AUTOSAR XML (schema 4-2-2)
package /STELLANTIS/EPT/ASWCs
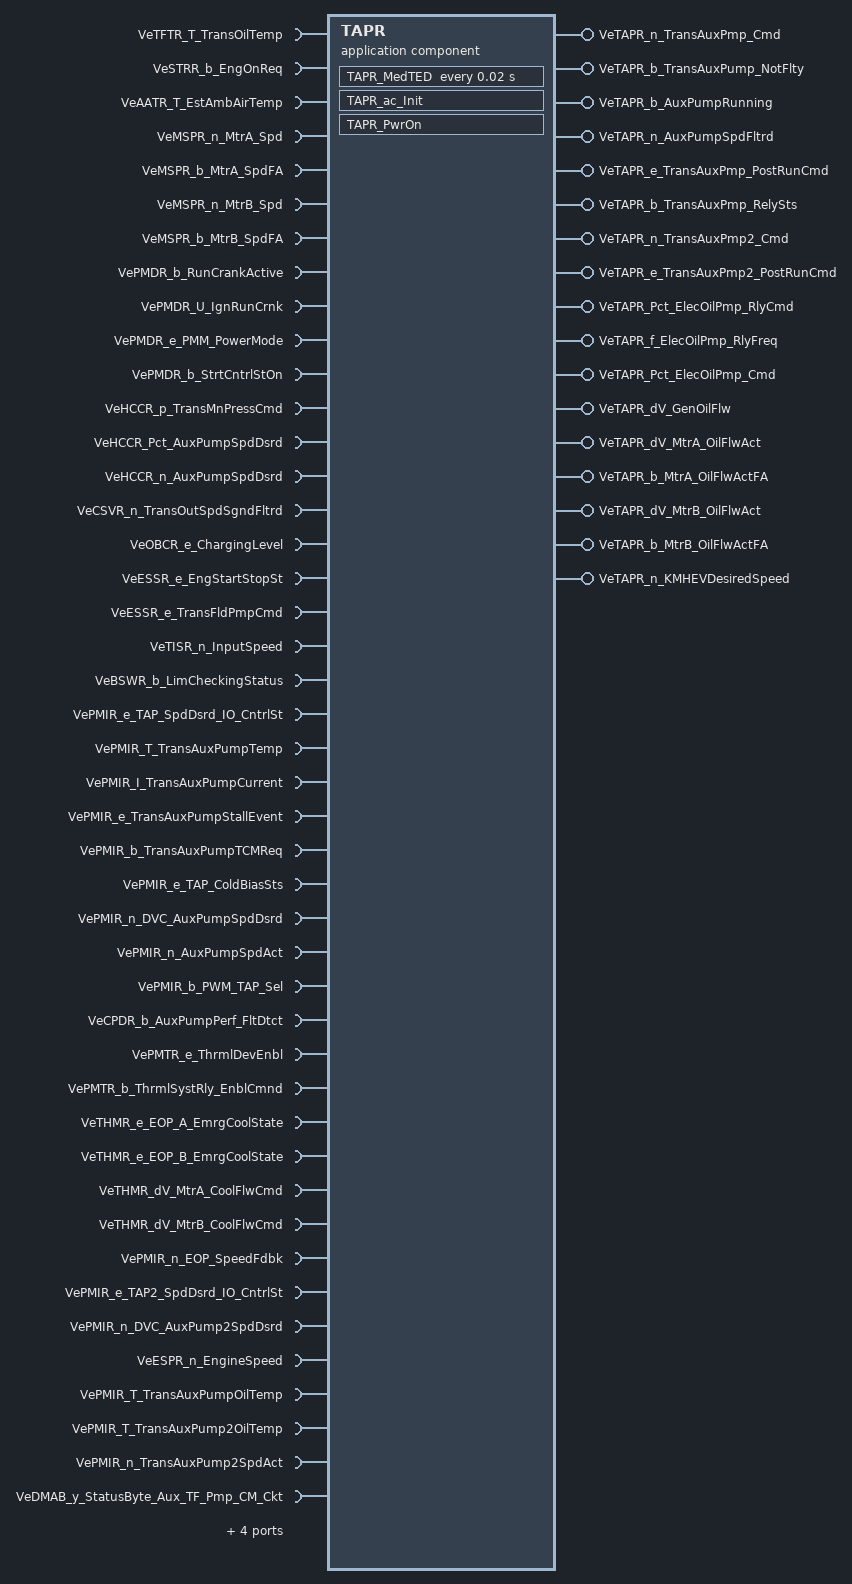
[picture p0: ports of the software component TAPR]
  application sw component type TAPR
    48 x require port:
      VeTFTR_T_TransOilTemp: variation-point={short-label=vpVeTFTR_T_TransOilTemp, sw-syscond=1}, nonqueued-receiver-com-spec{data-element=Value, init-value=0}, required-interface=VeTFTR_T_TransOilTemp
      VeSTRR_b_EngOnReq: variation-point={short-label=vpVeSTRR_b_EngOnReq, sw-syscond=1}, nonqueued-receiver-com-spec{data-element=Value, init-value=0}, required-interface=VeSTRR_b_EngOnReq
      VeAATR_T_EstAmbAirTemp: variation-point={short-label=vpVeAATR_T_EstAmbAirTemp, sw-syscond=1}, nonqueued-receiver-com-spec{data-element=Value, init-value=0}, required-interface=VeAATR_T_EstAmbAirTemp
      VeMSPR_n_MtrA_Spd: variation-point={short-label=vpVeMSPR_n_MtrA_Spd, sw-syscond=1}, nonqueued-receiver-com-spec{data-element=Value, init-value=0}, required-interface=VeMSPR_n_MtrA_Spd
      VeMSPR_b_MtrA_SpdFA: variation-point={short-label=vpVeMSPR_b_MtrA_SpdFA, sw-syscond=1}, nonqueued-receiver-com-spec{data-element=Value, init-value=0}, required-interface=VeMSPR_b_MtrA_SpdFA
      VeMSPR_n_MtrB_Spd: variation-point={short-label=vpVeMSPR_n_MtrB_Spd, sw-syscond=1}, nonqueued-receiver-com-spec{data-element=Value, init-value=0}, required-interface=VeMSPR_n_MtrB_Spd
      VeMSPR_b_MtrB_SpdFA: variation-point={short-label=vpVeMSPR_b_MtrB_SpdFA, sw-syscond=1}, nonqueued-receiver-com-spec{data-element=Value, init-value=0}, required-interface=VeMSPR_b_MtrB_SpdFA
      VePMDR_b_RunCrankActive: variation-point={short-label=vpVePMDR_b_RunCrankActive, sw-syscond=1}, nonqueued-receiver-com-spec{data-element=Value, init-value=0}, required-interface=VePMDR_b_RunCrankActive
      VePMDR_U_IgnRunCrnk: variation-point={short-label=vpVePMDR_U_IgnRunCrnk, sw-syscond=1}, nonqueued-receiver-com-spec{data-element=Value, init-value=0}, required-interface=VePMDR_U_IgnRunCrnk
      VePMDR_e_PMM_PowerMode: variation-point={short-label=vpVePMDR_e_PMM_PowerMode, sw-syscond=1}, nonqueued-receiver-com-spec{data-element=Value, init-value=CePMDR_e_PowerMode_Off}, required-interface=VePMDR_e_PMM_PowerMode
      VePMDR_b_StrtCntrlStOn: variation-point={short-label=vpVePMDR_b_StrtCntrlStOn, sw-syscond=1}, nonqueued-receiver-com-spec{data-element=Value, init-value=0}, required-interface=VePMDR_b_StrtCntrlStOn
      VeHCCR_p_TransMnPressCmd: variation-point={short-label=vpVeHCCR_p_TransMnPressCmd, sw-syscond=1}, nonqueued-receiver-com-spec{data-element=Value, init-value=0}, required-interface=VeHCCR_p_TransMnPressCmd
      VeHCCR_Pct_AuxPumpSpdDsrd: variation-point={short-label=vpVeHCCR_Pct_AuxPumpSpdDsrd, sw-syscond=1}, nonqueued-receiver-com-spec{data-element=Value, init-value=0}, required-interface=VeHCCR_Pct_AuxPumpSpdDsrd
      VeHCCR_n_AuxPumpSpdDsrd: variation-point={short-label=vpVeHCCR_n_AuxPumpSpdDsrd, sw-syscond=1}, nonqueued-receiver-com-spec{data-element=Value, init-value=0}, required-interface=VeHCCR_n_AuxPumpSpdDsrd
      VeCSVR_n_TransOutSpdSgndFltrd: variation-point={short-label=vpVeCSVR_n_TransOutSpdSgndFltrd, sw-syscond=1}, nonqueued-receiver-com-spec{data-element=Value, init-value=0}, required-interface=VeCSVR_n_TransOutSpdSgndFltrd
      VeOBCR_e_ChargingLevel: variation-point={short-label=vpVeOBCR_e_ChargingLevel, sw-syscond=1}, nonqueued-receiver-com-spec{data-element=Value, init-value=CeOBCR_e_ChargingLvlDefault}, required-interface=VeOBCR_e_ChargingLevel
      VeESSR_e_EngStartStopSt: variation-point={short-label=vpVeESSR_e_EngStartStopSt, sw-syscond=1}, nonqueued-receiver-com-spec{data-element=Value, init-value=CeESSR_e_EngOff}, required-interface=VeESSR_e_EngStartStopSt
      VeESSR_e_TransFldPmpCmd: variation-point={short-label=vpVeESSR_e_TransFldPmpCmd, sw-syscond=1}, nonqueued-receiver-com-spec{data-element=Value, init-value=CeESSR_e_Normal}, required-interface=VeESSR_e_TransFldPmpCmd
      VeTISR_n_InputSpeed: variation-point={short-label=vpVeTISR_n_InputSpeed, sw-syscond=1}, nonqueued-receiver-com-spec{data-element=Value, init-value=0}, required-interface=VeTISR_n_InputSpeed
      VeBSWR_b_LimCheckingStatus: variation-point={short-label=vpVeBSWR_b_LimCheckingStatus, sw-syscond=1}, nonqueued-receiver-com-spec{data-element=Value, init-value=0}, required-interface=VeBSWR_b_LimCheckingStatus
      VePMIR_e_TAP_SpdDsrd_IO_CntrlSt: variation-point={short-label=vpVePMIR_e_TAP_SpdDsrd_IO_CntrlSt, sw-syscond=1}, nonqueued-receiver-com-spec{data-element=Value, init-value=CeTAIR_e_Return_Control_to_ECU}, required-interface=VePMIR_e_TAP_SpdDsrd_IO_CntrlSt
      VePMIR_T_TransAuxPumpTemp: variation-point={short-label=vpVePMIR_T_TransAuxPumpTemp, sw-syscond=1}, nonqueued-receiver-com-spec{data-element=Value, init-value=0}, required-interface=VePMIR_T_TransAuxPumpTemp
      VePMIR_I_TransAuxPumpCurrent: variation-point={short-label=vpVePMIR_I_TransAuxPumpCurrent, sw-syscond=1}, nonqueued-receiver-com-spec{data-element=Value, init-value=0}, required-interface=VePMIR_I_TransAuxPumpCurrent
      VePMIR_e_TransAuxPumpStallEvent: variation-point={short-label=vpVePMIR_e_TransAuxPumpStallEvent, sw-syscond=1}, nonqueued-receiver-com-spec{data-element=Value, init-value=CeTAPR_e_StallEvnt_FALSE}, required-interface=VePMIR_e_TransAuxPumpStallEvent
      VePMIR_b_TransAuxPumpTCMReq: variation-point={short-label=vpVePMIR_b_TransAuxPumpTCMReq, sw-syscond=1}, nonqueued-receiver-com-spec{data-element=Value, init-value=0}, required-interface=VePMIR_b_TransAuxPumpTCMReq
      VePMIR_e_TAP_ColdBiasSts: variation-point={short-label=vpVePMIR_e_TAP_ColdBiasSts, sw-syscond=1}, nonqueued-receiver-com-spec{data-element=Value, init-value=CeTAPR_e_TAP_FalseTrueSNA_False}, required-interface=VePMIR_e_TAP_ColdBiasSts
      VePMIR_n_DVC_AuxPumpSpdDsrd: variation-point={short-label=vpVePMIR_n_DVC_AuxPumpSpdDsrd, sw-syscond=1}, nonqueued-receiver-com-spec{data-element=Value, init-value=0}, required-interface=VePMIR_n_DVC_AuxPumpSpdDsrd
      VePMIR_n_AuxPumpSpdAct: variation-point={short-label=vpVePMIR_n_AuxPumpSpdAct, sw-syscond=1}, nonqueued-receiver-com-spec{data-element=Value, init-value=0}, required-interface=VePMIR_n_AuxPumpSpdAct
      VePMIR_b_PWM_TAP_Sel: variation-point={short-label=vpVePMIR_b_PWM_TAP_Sel, sw-syscond=1}, nonqueued-receiver-com-spec{data-element=Value, init-value=0}, required-interface=VePMIR_b_PWM_TAP_Sel
      VeCPDR_b_AuxPumpPerf_FltDtct: variation-point={short-label=vpVeCPDR_b_AuxPumpPerf_FltDtct, sw-syscond=1}, nonqueued-receiver-com-spec{data-element=Value, init-value=0}, required-interface=VeCPDR_b_AuxPumpPerf_FltDtct
      VePMTR_e_ThrmlDevEnbl: variation-point={short-label=vpVePMTR_e_ThrmlDevEnbl, sw-syscond=1}, nonqueued-receiver-com-spec{data-element=Value, init-value=CePMTR_e_DISBL_All_Thrml}, required-interface=VePMTR_e_ThrmlDevEnbl
      VePMTR_b_ThrmlSystRly_EnblCmnd: variation-point={short-label=vpVePMTR_b_ThrmlSystRly_EnblCmnd, sw-syscond=1}, nonqueued-receiver-com-spec{data-element=Value, init-value=0}, required-interface=VePMTR_b_ThrmlSystRly_EnblCmnd
      VeTHMR_e_EOP_A_EmrgCoolState: variation-point={short-label=vpVeTHMR_e_EOP_A_EmrgCoolState, sw-syscond=1}, nonqueued-receiver-com-spec{data-element=Value, init-value=CeTHMR_e_OilPumpEmrgCool_OFF}, required-interface=VeTHMR_e_EOP_A_EmrgCoolState
      VeTHMR_e_EOP_B_EmrgCoolState: variation-point={short-label=vpVeTHMR_e_EOP_B_EmrgCoolState, sw-syscond=1}, nonqueued-receiver-com-spec{data-element=Value, init-value=CeTHMR_e_OilPumpEmrgCool_OFF}, required-interface=VeTHMR_e_EOP_B_EmrgCoolState
      VeTHMR_dV_MtrA_CoolFlwCmd: variation-point={short-label=vpVeTHMR_dV_MtrA_CoolFlwCmd, sw-syscond=1}, nonqueued-receiver-com-spec{data-element=Value, init-value=0}, required-interface=VeTHMR_dV_MtrA_CoolFlwCmd
      VeTHMR_dV_MtrB_CoolFlwCmd: variation-point={short-label=vpVeTHMR_dV_MtrB_CoolFlwCmd, sw-syscond=1}, nonqueued-receiver-com-spec{data-element=Value, init-value=0}, required-interface=VeTHMR_dV_MtrB_CoolFlwCmd
      VePMIR_n_EOP_SpeedFdbk: variation-point={short-label=vpVePMIR_n_EOP_SpeedFdbk, sw-syscond=1}, nonqueued-receiver-com-spec{data-element=Value, init-value=0}, required-interface=VePMIR_n_EOP_SpeedFdbk
      VePMIR_e_TAP2_SpdDsrd_IO_CntrlSt: variation-point={short-label=vpVePMIR_e_TAP2_SpdDsrd_IO_CntrlSt, sw-syscond=1}, nonqueued-receiver-com-spec{data-element=Value, init-value=CeTAIR_e_Return_Control_to_ECU}, required-interface=VePMIR_e_TAP2_SpdDsrd_IO_CntrlSt
      VePMIR_n_DVC_AuxPump2SpdDsrd: variation-point={short-label=vpVePMIR_n_DVC_AuxPump2SpdDsrd, sw-syscond=1}, nonqueued-receiver-com-spec{data-element=Value, init-value=0}, required-interface=VePMIR_n_DVC_AuxPump2SpdDsrd
      VeESPR_n_EngineSpeed: variation-point={short-label=vpVeESPR_n_EngineSpeed, sw-syscond=1}, nonqueued-receiver-com-spec{data-element=Value, init-value=0}, required-interface=VeESPR_n_EngineSpeed
      VePMIR_T_TransAuxPumpOilTemp: variation-point={short-label=vpVePMIR_T_TransAuxPumpOilTemp, sw-syscond=1}, nonqueued-receiver-com-spec{data-element=Value, init-value=0}, required-interface=VePMIR_T_TransAuxPumpOilTemp
      VePMIR_T_TransAuxPump2OilTemp: variation-point={short-label=vpVePMIR_T_TransAuxPump2OilTemp, sw-syscond=1}, nonqueued-receiver-com-spec{data-element=Value, init-value=0}, required-interface=VePMIR_T_TransAuxPump2OilTemp
      VePMIR_n_TransAuxPump2SpdAct: variation-point={short-label=vpVePMIR_n_TransAuxPump2SpdAct, sw-syscond=1}, nonqueued-receiver-com-spec{data-element=Value, init-value=0}, required-interface=VePMIR_n_TransAuxPump2SpdAct
      VeDMAB_y_StatusByte_Aux_TF_Pmp_CM_Ckt: nonqueued-receiver-com-spec{data-element=Value, init-value=0}, required-interface=VeDMAB_y_StatusByte_Aux_TF_Pmp_CM_Ckt
      VeDMAB_y_StatusByte_Aux_TF_Pmp_CM_Fdbck: nonqueued-receiver-com-spec{data-element=Value, init-value=0}, required-interface=VeDMAB_y_StatusByte_Aux_TF_Pmp_CM_Fdbck
      VeDMAB_y_StatusByte_Aux_TF_Pmp_CM_Fdbck_SigRan: nonqueued-receiver-com-spec{data-element=Value, init-value=0}, required-interface=VeDMAB_y_StatusByte_Aux_TF_Pmp_CM_Fdbck_SigRan
      VePMIR_e_PWM_EOP_IOCtrlMode: variation-point={short-label=vpVePMIR_e_PWM_EOP_IOCtrlMode, sw-syscond=1}, nonqueued-receiver-com-spec{data-element=Value, init-value=CeTAIR_e_Return_Control_to_ECU}, required-interface=VePMIR_e_PWM_EOP_IOCtrlMode
      VePMIR_Pct_PWM_EOP_IOCtrlSpd: variation-point={short-label=vpVePMIR_Pct_PWM_EOP_IOCtrlSpd, sw-syscond=1}, nonqueued-receiver-com-spec{data-element=Value, init-value=0}, required-interface=VePMIR_Pct_PWM_EOP_IOCtrlSpd
    17 x provide port:
      VeTAPR_n_TransAuxPmp_Cmd: variation-point={short-label=vpVeTAPR_n_TransAuxPmp_Cmd, sw-syscond=1}, nonqueued-sender-com-spec{data-element=Value, init-value=0}, provided-interface=VeTAPR_n_TransAuxPmp_Cmd
      VeTAPR_b_TransAuxPump_NotFlty: variation-point={short-label=vpVeTAPR_b_TransAuxPump_NotFlty, sw-syscond=1}, nonqueued-sender-com-spec{data-element=Value, init-value=0}, provided-interface=VeTAPR_b_TransAuxPump_NotFlty
      VeTAPR_b_AuxPumpRunning: variation-point={short-label=vpVeTAPR_b_AuxPumpRunning, sw-syscond=1}, nonqueued-sender-com-spec{data-element=Value, init-value=0}, provided-interface=VeTAPR_b_AuxPumpRunning
      VeTAPR_n_AuxPumpSpdFltrd: variation-point={short-label=vpVeTAPR_n_AuxPumpSpdFltrd, sw-syscond=1}, nonqueued-sender-com-spec{data-element=Value, init-value=0}, provided-interface=VeTAPR_n_AuxPumpSpdFltrd
      VeTAPR_e_TransAuxPmp_PostRunCmd: variation-point={short-label=vpVeTAPR_e_TransAuxPmp_PostRunCmd, sw-syscond=1}, nonqueued-sender-com-spec{data-element=Value, init-value=CeTAPR_e_TAP_PostRunCmd_NoPostRun}, provided-interface=VeTAPR_e_TransAuxPmp_PostRunCmd
      VeTAPR_b_TransAuxPmp_RelySts: variation-point={short-label=vpVeTAPR_b_TransAuxPmp_RelySts, sw-syscond=1}, nonqueued-sender-com-spec{data-element=Value, init-value=0}, provided-interface=VeTAPR_b_TransAuxPmp_RelySts
      VeTAPR_n_TransAuxPmp2_Cmd: variation-point={short-label=vpVeTAPR_n_TransAuxPmp2_Cmd, sw-syscond=1}, nonqueued-sender-com-spec{data-element=Value, init-value=0}, provided-interface=VeTAPR_n_TransAuxPmp2_Cmd
      VeTAPR_e_TransAuxPmp2_PostRunCmd: variation-point={short-label=vpVeTAPR_e_TransAuxPmp2_PostRunCmd, sw-syscond=1}, nonqueued-sender-com-spec{data-element=Value, init-value=CeTAPR_e_TAP_PostRunCmd_NoPostRun}, provided-interface=VeTAPR_e_TransAuxPmp2_PostRunCmd
      VeTAPR_Pct_ElecOilPmp_RlyCmd: variation-point={short-label=vpVeTAPR_Pct_ElecOilPmp_RlyCmd, sw-syscond=1}, nonqueued-sender-com-spec{data-element=Value, init-value=0}, provided-interface=VeTAPR_Pct_ElecOilPmp_RlyCmd
      VeTAPR_f_ElecOilPmp_RlyFreq: variation-point={short-label=vpVeTAPR_f_ElecOilPmp_RlyFreq, sw-syscond=1}, nonqueued-sender-com-spec{data-element=Value, init-value=0}, provided-interface=VeTAPR_f_ElecOilPmp_RlyFreq
      VeTAPR_Pct_ElecOilPmp_Cmd: variation-point={short-label=vpVeTAPR_Pct_ElecOilPmp_Cmd, sw-syscond=1}, nonqueued-sender-com-spec{data-element=Value, init-value=0}, provided-interface=VeTAPR_Pct_ElecOilPmp_Cmd
      VeTAPR_dV_GenOilFlw: variation-point={short-label=vpVeTAPR_dV_GenOilFlw, sw-syscond=1}, nonqueued-sender-com-spec{data-element=Value, init-value=0}, provided-interface=VeTAPR_dV_GenOilFlw
      VeTAPR_dV_MtrA_OilFlwAct: variation-point={short-label=vpVeTAPR_dV_MtrA_OilFlwAct, sw-syscond=1}, nonqueued-sender-com-spec{data-element=Value, init-value=0}, provided-interface=VeTAPR_dV_MtrA_OilFlwAct
      VeTAPR_b_MtrA_OilFlwActFA: variation-point={short-label=vpVeTAPR_b_MtrA_OilFlwActFA, sw-syscond=1}, nonqueued-sender-com-spec{data-element=Value, init-value=0}, provided-interface=VeTAPR_b_MtrA_OilFlwActFA
      VeTAPR_dV_MtrB_OilFlwAct: variation-point={short-label=vpVeTAPR_dV_MtrB_OilFlwAct, sw-syscond=1}, nonqueued-sender-com-spec{data-element=Value, init-value=0}, provided-interface=VeTAPR_dV_MtrB_OilFlwAct
      VeTAPR_b_MtrB_OilFlwActFA: variation-point={short-label=vpVeTAPR_b_MtrB_OilFlwActFA, sw-syscond=1}, nonqueued-sender-com-spec{data-element=Value, init-value=0}, provided-interface=VeTAPR_b_MtrB_OilFlwActFA
      VeTAPR_n_KMHEVDesiredSpeed: variation-point={short-label=vpVeTAPR_n_KMHEVDesiredSpeed, sw-syscond=1}, nonqueued-sender-com-spec{data-element=Value, init-value=0}, provided-interface=VeTAPR_n_KMHEVDesiredSpeed
    behavior IB_TAPR: data-type-mapping=msADTtoIDTMapping, handle-termination-and-restart=NO-SUPPORT
      timing event Event_MedTED: start-on-event=TAPR_MedTED, period=0.02
      init event Event_TAPR_ac_Init: start-on-event=TAPR_ac_Init
      init event Event_PwrOn: start-on-event=TAPR_PwrOn
      runnable TAPR_ac_Init
        data-send-points:
          access OUT_VeTAPR_e_TransAuxPmp_PostRunCmd_Value: accessed-variable=VeTAPR_e_TransAuxPmp_PostRunCmd.Value, variation-point={short-label=vpOUT_VeTAPR_e_TransAuxPmp_PostRunCmd_Value, sw-syscond=1}
          access OUT_VeTAPR_e_TransAuxPmp2_PostRunCmd_Value: accessed-variable=VeTAPR_e_TransAuxPmp2_PostRunCmd.Value, variation-point={short-label=vpOUT_VeTAPR_e_TransAuxPmp2_PostRunCmd_Value, sw-syscond=1}
      runnable TAPR_PwrOn
        data-send-points:
          17 x access:
            OUT_VeTAPR_b_TransAuxPmp_RelySts_Value: accessed-variable=VeTAPR_b_TransAuxPmp_RelySts.Value, variation-point={short-label=vpOUT_VeTAPR_b_TransAuxPmp_RelySts_Value, sw-syscond=1}
            OUT_VeTAPR_e_TransAuxPmp2_PostRunCmd_Value: accessed-variable=VeTAPR_e_TransAuxPmp2_PostRunCmd.Value, variation-point={short-label=vpOUT_VeTAPR_e_TransAuxPmp2_PostRunCmd_Value, sw-syscond=1}
            OUT_VeTAPR_n_TransAuxPmp_Cmd_Value: accessed-variable=VeTAPR_n_TransAuxPmp_Cmd.Value, variation-point={short-label=vpOUT_VeTAPR_n_TransAuxPmp_Cmd_Value, sw-syscond=1}
            OUT_VeTAPR_b_TransAuxPump_NotFlty_Value: accessed-variable=VeTAPR_b_TransAuxPump_NotFlty.Value, variation-point={short-label=vpOUT_VeTAPR_b_TransAuxPump_NotFlty_Value, sw-syscond=1}
            OUT_VeTAPR_n_AuxPumpSpdFltrd_Value: accessed-variable=VeTAPR_n_AuxPumpSpdFltrd.Value, variation-point={short-label=vpOUT_VeTAPR_n_AuxPumpSpdFltrd_Value, sw-syscond=1}
            OUT_VeTAPR_e_TransAuxPmp_PostRunCmd_Value: accessed-variable=VeTAPR_e_TransAuxPmp_PostRunCmd.Value, variation-point={short-label=vpOUT_VeTAPR_e_TransAuxPmp_PostRunCmd_Value, sw-syscond=1}
            OUT_VeTAPR_b_AuxPumpRunning_Value: accessed-variable=VeTAPR_b_AuxPumpRunning.Value, variation-point={short-label=vpOUT_VeTAPR_b_AuxPumpRunning_Value, sw-syscond=1}
            OUT_VeTAPR_Pct_ElecOilPmp_RlyCmd_Value: accessed-variable=VeTAPR_Pct_ElecOilPmp_RlyCmd.Value, variation-point={short-label=vpOUT_VeTAPR_Pct_ElecOilPmp_RlyCmd_Value, sw-syscond=1}
            OUT_VeTAPR_Pct_ElecOilPmp_Cmd_Value: accessed-variable=VeTAPR_Pct_ElecOilPmp_Cmd.Value, variation-point={short-label=vpOUT_VeTAPR_Pct_ElecOilPmp_Cmd_Value, sw-syscond=1}
            OUT_VeTAPR_f_ElecOilPmp_RlyFreq_Value: accessed-variable=VeTAPR_f_ElecOilPmp_RlyFreq.Value, variation-point={short-label=vpOUT_VeTAPR_f_ElecOilPmp_RlyFreq_Value, sw-syscond=1}
            OUT_VeTAPR_n_TransAuxPmp2_Cmd_Value: accessed-variable=VeTAPR_n_TransAuxPmp2_Cmd.Value, variation-point={short-label=vpOUT_VeTAPR_n_TransAuxPmp2_Cmd_Value, sw-syscond=1}
            OUT_VeTAPR_dV_GenOilFlw_Value: accessed-variable=VeTAPR_dV_GenOilFlw.Value, variation-point={short-label=vpOUT_VeTAPR_dV_GenOilFlw_Value, sw-syscond=1}
            OUT_VeTAPR_dV_MtrA_OilFlwAct_Value: accessed-variable=VeTAPR_dV_MtrA_OilFlwAct.Value, variation-point={short-label=vpOUT_VeTAPR_dV_MtrA_OilFlwAct_Value, sw-syscond=1}
            OUT_VeTAPR_b_MtrA_OilFlwActFA_Value: accessed-variable=VeTAPR_b_MtrA_OilFlwActFA.Value, variation-point={short-label=vpOUT_VeTAPR_b_MtrA_OilFlwActFA_Value, sw-syscond=1}
            OUT_VeTAPR_dV_MtrB_OilFlwAct_Value: accessed-variable=VeTAPR_dV_MtrB_OilFlwAct.Value, variation-point={short-label=vpOUT_VeTAPR_dV_MtrB_OilFlwAct_Value, sw-syscond=1}
            OUT_VeTAPR_b_MtrB_OilFlwActFA_Value: accessed-variable=VeTAPR_b_MtrB_OilFlwActFA.Value, variation-point={short-label=vpOUT_VeTAPR_b_MtrB_OilFlwActFA_Value, sw-syscond=1}
            OUT_VeTAPR_n_KMHEVDesiredSpeed_Value: accessed-variable=VeTAPR_n_KMHEVDesiredSpeed.Value, variation-point={short-label=vpOUT_VeTAPR_n_KMHEVDesiredSpeed_Value, sw-syscond=1}
      runnable TAPR_MedTED
        data-receive-point-by-arguments:
          48 x access:
            IN_VeAATR_T_EstAmbAirTemp_Value: accessed-variable=VeAATR_T_EstAmbAirTemp.Value, variation-point={short-label=vpIN_VeAATR_T_EstAmbAirTemp_Value, sw-syscond=1}
            IN_VeBSWR_b_LimCheckingStatus_Value: accessed-variable=VeBSWR_b_LimCheckingStatus.Value, variation-point={short-label=vpIN_VeBSWR_b_LimCheckingStatus_Value, sw-syscond=1}
            IN_VeCPDR_b_AuxPumpPerf_FltDtct_Value: accessed-variable=VeCPDR_b_AuxPumpPerf_FltDtct.Value, variation-point={short-label=vpIN_VeCPDR_b_AuxPumpPerf_FltDtct_Value, sw-syscond=1}
            IN_VeCSVR_n_TransOutSpdSgndFltrd_Value: accessed-variable=VeCSVR_n_TransOutSpdSgndFltrd.Value, variation-point={short-label=vpIN_VeCSVR_n_TransOutSpdSgndFltrd_Value, sw-syscond=1}
            IN_VeDMAB_y_StatusByte_Aux_TF_Pmp_CM_Ckt_Value: accessed-variable=VeDMAB_y_StatusByte_Aux_TF_Pmp_CM_Ckt.Value
            IN_VeDMAB_y_StatusByte_Aux_TF_Pmp_CM_Fdbck_Value: accessed-variable=VeDMAB_y_StatusByte_Aux_TF_Pmp_CM_Fdbck.Value
            IN_VeDMAB_y_StatusByte_Aux_TF_Pmp_CM_Fdbck_SigRan_Value: accessed-variable=VeDMAB_y_StatusByte_Aux_TF_Pmp_CM_Fdbck_SigRan.Value
            IN_VeESPR_n_EngineSpeed_Value: accessed-variable=VeESPR_n_EngineSpeed.Value, variation-point={short-label=vpIN_VeESPR_n_EngineSpeed_Value, sw-syscond=1}
            IN_VeESSR_e_EngStartStopSt_Value: accessed-variable=VeESSR_e_EngStartStopSt.Value, variation-point={short-label=vpIN_VeESSR_e_EngStartStopSt_Value, sw-syscond=1}
            IN_VeESSR_e_TransFldPmpCmd_Value: accessed-variable=VeESSR_e_TransFldPmpCmd.Value, variation-point={short-label=vpIN_VeESSR_e_TransFldPmpCmd_Value, sw-syscond=1}
            IN_VeHCCR_Pct_AuxPumpSpdDsrd_Value: accessed-variable=VeHCCR_Pct_AuxPumpSpdDsrd.Value, variation-point={short-label=vpIN_VeHCCR_Pct_AuxPumpSpdDsrd_Value, sw-syscond=1}
            IN_VeHCCR_n_AuxPumpSpdDsrd_Value: accessed-variable=VeHCCR_n_AuxPumpSpdDsrd.Value, variation-point={short-label=vpIN_VeHCCR_n_AuxPumpSpdDsrd_Value, sw-syscond=1}
            IN_VeHCCR_p_TransMnPressCmd_Value: accessed-variable=VeHCCR_p_TransMnPressCmd.Value, variation-point={short-label=vpIN_VeHCCR_p_TransMnPressCmd_Value, sw-syscond=1}
            IN_VeMSPR_b_MtrA_SpdFA_Value: accessed-variable=VeMSPR_b_MtrA_SpdFA.Value, variation-point={short-label=vpIN_VeMSPR_b_MtrA_SpdFA_Value, sw-syscond=1}
            IN_VeMSPR_b_MtrB_SpdFA_Value: accessed-variable=VeMSPR_b_MtrB_SpdFA.Value, variation-point={short-label=vpIN_VeMSPR_b_MtrB_SpdFA_Value, sw-syscond=1}
            IN_VeMSPR_n_MtrA_Spd_Value: accessed-variable=VeMSPR_n_MtrA_Spd.Value, variation-point={short-label=vpIN_VeMSPR_n_MtrA_Spd_Value, sw-syscond=1}
            IN_VeMSPR_n_MtrB_Spd_Value: accessed-variable=VeMSPR_n_MtrB_Spd.Value, variation-point={short-label=vpIN_VeMSPR_n_MtrB_Spd_Value, sw-syscond=1}
            IN_VeOBCR_e_ChargingLevel_Value: accessed-variable=VeOBCR_e_ChargingLevel.Value, variation-point={short-label=vpIN_VeOBCR_e_ChargingLevel_Value, sw-syscond=1}
            IN_VePMDR_U_IgnRunCrnk_Value: accessed-variable=VePMDR_U_IgnRunCrnk.Value, variation-point={short-label=vpIN_VePMDR_U_IgnRunCrnk_Value, sw-syscond=1}
            IN_VePMDR_b_RunCrankActive_Value: accessed-variable=VePMDR_b_RunCrankActive.Value, variation-point={short-label=vpIN_VePMDR_b_RunCrankActive_Value, sw-syscond=1}
            IN_VePMDR_b_StrtCntrlStOn_Value: accessed-variable=VePMDR_b_StrtCntrlStOn.Value, variation-point={short-label=vpIN_VePMDR_b_StrtCntrlStOn_Value, sw-syscond=1}
            IN_VePMDR_e_PMM_PowerMode_Value: accessed-variable=VePMDR_e_PMM_PowerMode.Value, variation-point={short-label=vpIN_VePMDR_e_PMM_PowerMode_Value, sw-syscond=1}
            IN_VePMIR_I_TransAuxPumpCurrent_Value: accessed-variable=VePMIR_I_TransAuxPumpCurrent.Value, variation-point={short-label=vpIN_VePMIR_I_TransAuxPumpCurrent_Value, sw-syscond=1}
            IN_VePMIR_Pct_PWM_EOP_IOCtrlSpd_Value: accessed-variable=VePMIR_Pct_PWM_EOP_IOCtrlSpd.Value, variation-point={short-label=vpIN_VePMIR_Pct_PWM_EOP_IOCtrlSpd_Value, sw-syscond=1}
            IN_VePMIR_T_TransAuxPump2OilTemp_Value: accessed-variable=VePMIR_T_TransAuxPump2OilTemp.Value, variation-point={short-label=vpIN_VePMIR_T_TransAuxPump2OilTemp_Value, sw-syscond=1}
            IN_VePMIR_T_TransAuxPumpOilTemp_Value: accessed-variable=VePMIR_T_TransAuxPumpOilTemp.Value, variation-point={short-label=vpIN_VePMIR_T_TransAuxPumpOilTemp_Value, sw-syscond=1}
            IN_VePMIR_T_TransAuxPumpTemp_Value: accessed-variable=VePMIR_T_TransAuxPumpTemp.Value, variation-point={short-label=vpIN_VePMIR_T_TransAuxPumpTemp_Value, sw-syscond=1}
            IN_VePMIR_b_PWM_TAP_Sel_Value: accessed-variable=VePMIR_b_PWM_TAP_Sel.Value, variation-point={short-label=vpIN_VePMIR_b_PWM_TAP_Sel_Value, sw-syscond=1}
            IN_VePMIR_b_TransAuxPumpTCMReq_Value: accessed-variable=VePMIR_b_TransAuxPumpTCMReq.Value, variation-point={short-label=vpIN_VePMIR_b_TransAuxPumpTCMReq_Value, sw-syscond=1}
            IN_VePMIR_e_PWM_EOP_IOCtrlMode_Value: accessed-variable=VePMIR_e_PWM_EOP_IOCtrlMode.Value, variation-point={short-label=vpIN_VePMIR_e_PWM_EOP_IOCtrlMode_Value, sw-syscond=1}
            IN_VePMIR_e_TAP2_SpdDsrd_IO_CntrlSt_Value: accessed-variable=VePMIR_e_TAP2_SpdDsrd_IO_CntrlSt.Value, variation-point={short-label=vpIN_VePMIR_e_TAP2_SpdDsrd_IO_CntrlSt_Value, sw-syscond=1}
            IN_VePMIR_e_TAP_ColdBiasSts_Value: accessed-variable=VePMIR_e_TAP_ColdBiasSts.Value, variation-point={short-label=vpIN_VePMIR_e_TAP_ColdBiasSts_Value, sw-syscond=1}
            IN_VePMIR_e_TAP_SpdDsrd_IO_CntrlSt_Value: accessed-variable=VePMIR_e_TAP_SpdDsrd_IO_CntrlSt.Value, variation-point={short-label=vpIN_VePMIR_e_TAP_SpdDsrd_IO_CntrlSt_Value, sw-syscond=1}
            IN_VePMIR_e_TransAuxPumpStallEvent_Value: accessed-variable=VePMIR_e_TransAuxPumpStallEvent.Value, variation-point={short-label=vpIN_VePMIR_e_TransAuxPumpStallEvent_Value, sw-syscond=1}
            IN_VePMIR_n_AuxPumpSpdAct_Value: accessed-variable=VePMIR_n_AuxPumpSpdAct.Value, variation-point={short-label=vpIN_VePMIR_n_AuxPumpSpdAct_Value, sw-syscond=1}
            IN_VePMIR_n_DVC_AuxPump2SpdDsrd_Value: accessed-variable=VePMIR_n_DVC_AuxPump2SpdDsrd.Value, variation-point={short-label=vpIN_VePMIR_n_DVC_AuxPump2SpdDsrd_Value, sw-syscond=1}
            IN_VePMIR_n_DVC_AuxPumpSpdDsrd_Value: accessed-variable=VePMIR_n_DVC_AuxPumpSpdDsrd.Value, variation-point={short-label=vpIN_VePMIR_n_DVC_AuxPumpSpdDsrd_Value, sw-syscond=1}
            IN_VePMIR_n_EOP_SpeedFdbk_Value: accessed-variable=VePMIR_n_EOP_SpeedFdbk.Value, variation-point={short-label=vpIN_VePMIR_n_EOP_SpeedFdbk_Value, sw-syscond=1}
            IN_VePMIR_n_TransAuxPump2SpdAct_Value: accessed-variable=VePMIR_n_TransAuxPump2SpdAct.Value, variation-point={short-label=vpIN_VePMIR_n_TransAuxPump2SpdAct_Value, sw-syscond=1}
            IN_VePMTR_b_ThrmlSystRly_EnblCmnd_Value: accessed-variable=VePMTR_b_ThrmlSystRly_EnblCmnd.Value, variation-point={short-label=vpIN_VePMTR_b_ThrmlSystRly_EnblCmnd_Value, sw-syscond=1}
            IN_VePMTR_e_ThrmlDevEnbl_Value: accessed-variable=VePMTR_e_ThrmlDevEnbl.Value, variation-point={short-label=vpIN_VePMTR_e_ThrmlDevEnbl_Value, sw-syscond=1}
            IN_VeSTRR_b_EngOnReq_Value: accessed-variable=VeSTRR_b_EngOnReq.Value, variation-point={short-label=vpIN_VeSTRR_b_EngOnReq_Value, sw-syscond=1}
            IN_VeTFTR_T_TransOilTemp_Value: accessed-variable=VeTFTR_T_TransOilTemp.Value, variation-point={short-label=vpIN_VeTFTR_T_TransOilTemp_Value, sw-syscond=1}
            IN_VeTHMR_dV_MtrA_CoolFlwCmd_Value: accessed-variable=VeTHMR_dV_MtrA_CoolFlwCmd.Value, variation-point={short-label=vpIN_VeTHMR_dV_MtrA_CoolFlwCmd_Value, sw-syscond=1}
            IN_VeTHMR_dV_MtrB_CoolFlwCmd_Value: accessed-variable=VeTHMR_dV_MtrB_CoolFlwCmd.Value, variation-point={short-label=vpIN_VeTHMR_dV_MtrB_CoolFlwCmd_Value, sw-syscond=1}
            IN_VeTHMR_e_EOP_A_EmrgCoolState_Value: accessed-variable=VeTHMR_e_EOP_A_EmrgCoolState.Value, variation-point={short-label=vpIN_VeTHMR_e_EOP_A_EmrgCoolState_Value, sw-syscond=1}
            IN_VeTHMR_e_EOP_B_EmrgCoolState_Value: accessed-variable=VeTHMR_e_EOP_B_EmrgCoolState.Value, variation-point={short-label=vpIN_VeTHMR_e_EOP_B_EmrgCoolState_Value, sw-syscond=1}
            IN_VeTISR_n_InputSpeed_Value: accessed-variable=VeTISR_n_InputSpeed.Value, variation-point={short-label=vpIN_VeTISR_n_InputSpeed_Value, sw-syscond=1}
        data-send-points:
          17 x access:
            OUT_VeTAPR_b_TransAuxPmp_RelySts_Value: accessed-variable=VeTAPR_b_TransAuxPmp_RelySts.Value, variation-point={short-label=vpOUT_VeTAPR_b_TransAuxPmp_RelySts_Value, sw-syscond=1}
            OUT_VeTAPR_e_TransAuxPmp2_PostRunCmd_Value: accessed-variable=VeTAPR_e_TransAuxPmp2_PostRunCmd.Value, variation-point={short-label=vpOUT_VeTAPR_e_TransAuxPmp2_PostRunCmd_Value, sw-syscond=1}
            OUT_VeTAPR_n_TransAuxPmp_Cmd_Value: accessed-variable=VeTAPR_n_TransAuxPmp_Cmd.Value, variation-point={short-label=vpOUT_VeTAPR_n_TransAuxPmp_Cmd_Value, sw-syscond=1}
            OUT_VeTAPR_b_TransAuxPump_NotFlty_Value: accessed-variable=VeTAPR_b_TransAuxPump_NotFlty.Value, variation-point={short-label=vpOUT_VeTAPR_b_TransAuxPump_NotFlty_Value, sw-syscond=1}
            OUT_VeTAPR_n_AuxPumpSpdFltrd_Value: accessed-variable=VeTAPR_n_AuxPumpSpdFltrd.Value, variation-point={short-label=vpOUT_VeTAPR_n_AuxPumpSpdFltrd_Value, sw-syscond=1}
            OUT_VeTAPR_e_TransAuxPmp_PostRunCmd_Value: accessed-variable=VeTAPR_e_TransAuxPmp_PostRunCmd.Value, variation-point={short-label=vpOUT_VeTAPR_e_TransAuxPmp_PostRunCmd_Value, sw-syscond=1}
            OUT_VeTAPR_b_AuxPumpRunning_Value: accessed-variable=VeTAPR_b_AuxPumpRunning.Value, variation-point={short-label=vpOUT_VeTAPR_b_AuxPumpRunning_Value, sw-syscond=1}
            OUT_VeTAPR_Pct_ElecOilPmp_RlyCmd_Value: accessed-variable=VeTAPR_Pct_ElecOilPmp_RlyCmd.Value, variation-point={short-label=vpOUT_VeTAPR_Pct_ElecOilPmp_RlyCmd_Value, sw-syscond=1}
            OUT_VeTAPR_Pct_ElecOilPmp_Cmd_Value: accessed-variable=VeTAPR_Pct_ElecOilPmp_Cmd.Value, variation-point={short-label=vpOUT_VeTAPR_Pct_ElecOilPmp_Cmd_Value, sw-syscond=1}
            OUT_VeTAPR_f_ElecOilPmp_RlyFreq_Value: accessed-variable=VeTAPR_f_ElecOilPmp_RlyFreq.Value, variation-point={short-label=vpOUT_VeTAPR_f_ElecOilPmp_RlyFreq_Value, sw-syscond=1}
            OUT_VeTAPR_n_TransAuxPmp2_Cmd_Value: accessed-variable=VeTAPR_n_TransAuxPmp2_Cmd.Value, variation-point={short-label=vpOUT_VeTAPR_n_TransAuxPmp2_Cmd_Value, sw-syscond=1}
            OUT_VeTAPR_dV_GenOilFlw_Value: accessed-variable=VeTAPR_dV_GenOilFlw.Value, variation-point={short-label=vpOUT_VeTAPR_dV_GenOilFlw_Value, sw-syscond=1}
            OUT_VeTAPR_dV_MtrA_OilFlwAct_Value: accessed-variable=VeTAPR_dV_MtrA_OilFlwAct.Value, variation-point={short-label=vpOUT_VeTAPR_dV_MtrA_OilFlwAct_Value, sw-syscond=1}
            OUT_VeTAPR_b_MtrA_OilFlwActFA_Value: accessed-variable=VeTAPR_b_MtrA_OilFlwActFA.Value, variation-point={short-label=vpOUT_VeTAPR_b_MtrA_OilFlwActFA_Value, sw-syscond=1}
            OUT_VeTAPR_dV_MtrB_OilFlwAct_Value: accessed-variable=VeTAPR_dV_MtrB_OilFlwAct.Value, variation-point={short-label=vpOUT_VeTAPR_dV_MtrB_OilFlwAct_Value, sw-syscond=1}
            OUT_VeTAPR_b_MtrB_OilFlwActFA_Value: accessed-variable=VeTAPR_b_MtrB_OilFlwActFA.Value, variation-point={short-label=vpOUT_VeTAPR_b_MtrB_OilFlwActFA_Value, sw-syscond=1}
            OUT_VeTAPR_n_KMHEVDesiredSpeed_Value: accessed-variable=VeTAPR_n_KMHEVDesiredSpeed.Value, variation-point={short-label=vpOUT_VeTAPR_n_KMHEVDesiredSpeed_Value, sw-syscond=1}
      variation point proxy Variant_TAPR_FUNC_1: category=CONDITION, condition-access=1
      variation point proxy Variant_TAPR_FUNC_2: category=CONDITION, condition-access=0
      variation point proxy Variant_TAPR_FUNC_3: category=CONDITION, condition-access=0
